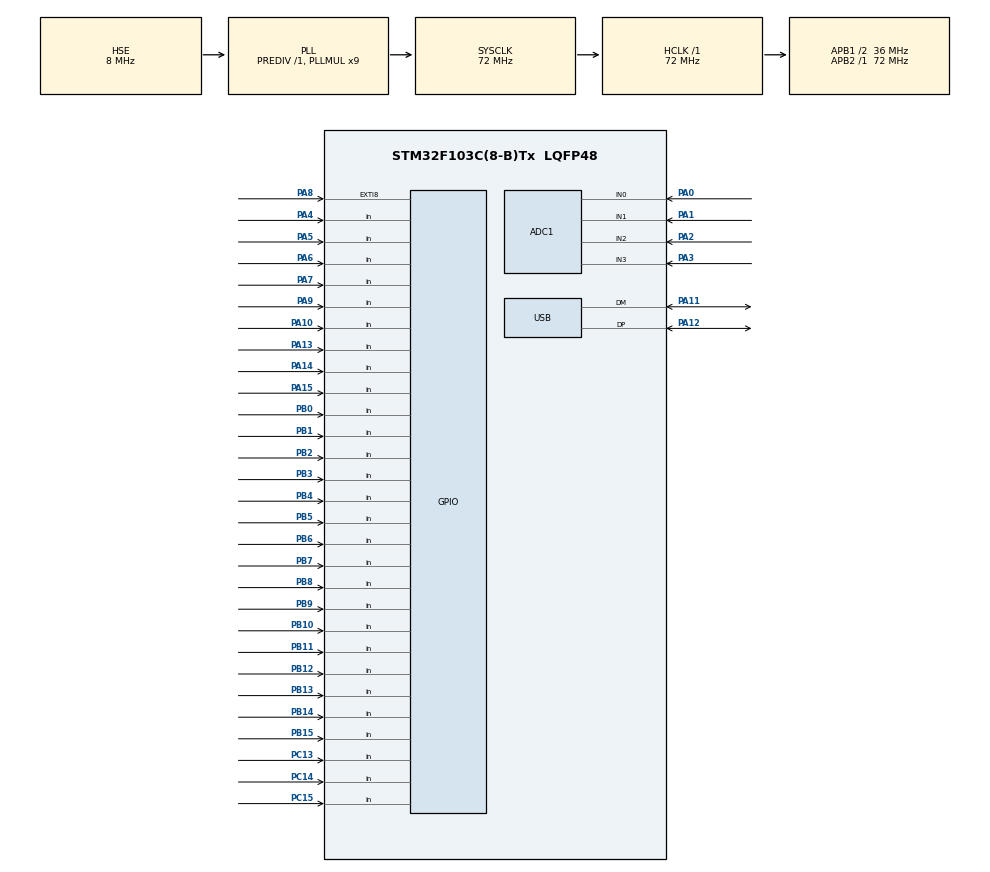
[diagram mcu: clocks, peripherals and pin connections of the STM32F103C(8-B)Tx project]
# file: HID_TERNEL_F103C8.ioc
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ADC1.Channel-0\#ChannelRegularConversion=ADC_CHANNEL_0
ADC1.Channel-1\#ChannelRegularConversion=ADC_CHANNEL_1
ADC1.Channel-2\#ChannelRegularConversion=ADC_CHANNEL_2
ADC1.Channel-3\#ChannelRegularConversion=ADC_CHANNEL_3
ADC1.ContinuousConvMode=ENABLE
ADC1.NbrOfConversion=4
ADC1.NbrOfConversionFlag=1
ADC1.Rank-0\#ChannelRegularConversion=1
ADC1.Rank-1\#ChannelRegularConversion=2
ADC1.Rank-2\#ChannelRegularConversion=3
ADC1.Rank-3\#ChannelRegularConversion=4
ADC1.SamplingTime-0\#ChannelRegularConversion=ADC_SAMPLETIME_71CYCLES_5
ADC1.SamplingTime-1\#ChannelRegularConversion=ADC_SAMPLETIME_71CYCLES_5
ADC1.SamplingTime-2\#ChannelRegularConversion=ADC_SAMPLETIME_71CYCLES_5
ADC1.SamplingTime-3\#ChannelRegularConversion=ADC_SAMPLETIME_71CYCLES_5
ADC1.master=1
Dma.ADC1.0.Direction=DMA_PERIPH_TO_MEMORY
Dma.ADC1.0.Instance=DMA1_Channel1
Dma.ADC1.0.MemDataAlignment=DMA_MDATAALIGN_HALFWORD
Dma.ADC1.0.MemInc=DMA_MINC_ENABLE
Dma.ADC1.0.Mode=DMA_CIRCULAR
Dma.ADC1.0.PeriphDataAlignment=DMA_PDATAALIGN_HALFWORD
Dma.ADC1.0.PeriphInc=DMA_PINC_DISABLE
Dma.ADC1.0.Priority=DMA_PRIORITY_MEDIUM
Dma.Request0=ADC1
Mcu.Family=STM32F1
Mcu.Name=STM32F103C(8-B)Tx
Mcu.Package=LQFP48
NVIC.ADC1_2_IRQn=true\:0\:0\:false\:false\:true\:true\:true\:true
NVIC.DMA1_Channel1_IRQn=true\:0\:0\:false\:false\:true\:false\:true\:true
NVIC.PriorityGroup=NVIC_PRIORITYGROUP_4
NVIC.TIM2_IRQn=true\:0\:0\:false\:false\:true\:true\:true\:true
NVIC.USB_LP_CAN1_RX0_IRQn=true\:0\:0\:false\:false\:true\:false\:true\:true
PA0-WKUP.Signal=ADCx_IN0
PA1.Signal=ADCx_IN1
PA10.Signal=GPIO_Input
PA11.Mode=Device
PA11.Signal=USB_DM
PA12.Mode=Device
PA12.Signal=USB_DP
PA13.Signal=GPIO_Input
PA14.Signal=GPIO_Input
PA15.Signal=GPIO_Input
PA2.Signal=ADCx_IN2
PA3.Signal=ADCx_IN3
PA4.Signal=GPIO_Input
PA5.Signal=GPIO_Input
PA6.Signal=GPIO_Input
PA7.Signal=GPIO_Input
PA8.Signal=GPXTI8
PA9.Signal=GPIO_Input
PB0.Signal=GPIO_Input
PB1.Signal=GPIO_Input
PB10.Signal=GPIO_Input
PB11.Signal=GPIO_Input
PB12.Signal=GPIO_Input
PB13.Signal=GPIO_Input
PB14.Signal=GPIO_Input
PB15.Signal=GPIO_Input
PB2.Signal=GPIO_Input
PB3.Signal=GPIO_Input
PB4.Signal=GPIO_Input
PB5.Signal=GPIO_Input
PB6.Signal=GPIO_Input
PB7.Signal=GPIO_Input
PB8.Signal=GPIO_Input
PB9.Signal=GPIO_Input
PC13-TAMPER-RTC.Signal=GPIO_Input
PC14-OSC32_IN.Signal=GPIO_Input
PC15-OSC32_OUT.Signal=GPIO_Input
PD0-OSC_IN.Mode=HSE-External-Oscillator
PD0-OSC_IN.Signal=RCC_OSC_IN
PD1-OSC_OUT.Mode=HSE-External-Oscillator
PD1-OSC_OUT.Signal=RCC_OSC_OUT
ProjectManager.HeapSize=0x200
ProjectManager.StackSize=0x400
ProjectManager.TargetToolchain=Makefile
RCC.ADCPresc=RCC_ADCPCLK2_DIV6
RCC.AHBFreq_Value=72000000
RCC.APB1CLKDivider=RCC_HCLK_DIV2
RCC.APB1Freq_Value=36000000
RCC.APB1TimFreq_Value=72000000
RCC.APB2Freq_Value=72000000
RCC.APB2TimFreq_Value=72000000
RCC.HCLKFreq_Value=72000000
RCC.PLLMUL=RCC_PLL_MUL9
RCC.SYSCLKFreq_VALUE=72000000
RCC.SYSCLKSource=RCC_SYSCLKSOURCE_PLLCLK
RCC.USBFreq_Value=48000000
RCC.USBPrescaler=RCC_USBCLKSOURCE_PLL_DIV1_5
SH.ADCx_IN0.0=ADC1_IN0,IN0
SH.ADCx_IN1.0=ADC1_IN1,IN1
SH.ADCx_IN2.0=ADC1_IN2,IN2
SH.ADCx_IN3.0=ADC1_IN3,IN3
TIM2.AutoReloadPreload=TIM_AUTORELOAD_PRELOAD_ENABLE
TIM2.Period=99
TIM2.Prescaler=71
USB_DEVICE.CLASS_NAME_FS=CUSTOM_HID
USB_DEVICE.CUSTOM_HID_FS_BINTERVAL=0x1
USB_DEVICE.MANUFACTURER_STRING=STMicroelectronics
USB_DEVICE.PID_CUSTOMHID_FS=22353
USB_DEVICE.PRODUCT_STRING_CUSTOMHID_FS=HID_throttle
USB_DEVICE.USBD_CUSTOMHID_OUTREPORT_BUF_SIZE=64
USB_DEVICE.USBD_CUSTOM_HID_REPORT_DESC_SIZE=50
USB_DEVICE.VID=1154
USB_DEVICE.VirtualMode=CustomHid
USB_DEVICE.VirtualModeFS=Custom_Hid_FS
VP_SYS_VS_ND.Mode=No_Debug
VP_TIM2_VS_ClockSourceINT.Mode=Internal
VP_USB_DEVICE_VS_USB_DEVICE_CUSTOM_HID_FS.Mode=CUSTOM_HID_FS
board=custom

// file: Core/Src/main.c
/* USER CODE BEGIN Header */
/**
  ******************************************************************************
  * @file           : main.c
  * @brief          : Main program body
  ******************************************************************************
  * @attention
  *
  * Copyright (c) 2025 STMicroelectronics.
  * All rights reserved.
  *
  * This software is licensed under terms that can be found in the LICENSE file
  * in the root directory of this software component.
  * If no LICENSE file comes with this software, it is provided AS-IS.
  *
  ******************************************************************************
  */
/* USER CODE END Header */
#include "main.h"
#include "adc.h"
#include "dma.h"
#include "tim.h"
#include "usb_device.h"
#include "gpio.h"

/* USER CODE BEGIN Includes */
#include "hid_device_for_handel.h"
/* USER CODE END Includes */

void SystemClock_Config(void);

int main(void)
{

  /* MCU Configuration--------------------------------------------------------*/

  /* Reset of all peripherals, Initializes the Flash interface and the Systick. */
  HAL_Init();

  /* Configure the system clock */
  SystemClock_Config();

  /* Initialize all configured peripherals */
  MX_GPIO_Init();
  MX_DMA_Init();
  MX_ADC1_Init();
  MX_TIM2_Init();
  MX_USB_DEVICE_Init();
  /* USER CODE BEGIN 2 */
  HID_FLIGHT_SIMULATOR_SYS_START();

  /* USER CODE END 2 */

  /* Infinite loop */
  /* USER CODE BEGIN WHILE */
  while (1)
  {
    HID_FLIGHT_SIMULATOR_SYS_LOOP();
    /* USER CODE END WHILE */

  }
}

void SystemClock_Config(void)
{
  RCC_OscInitTypeDef RCC_OscInitStruct = {0};
  RCC_ClkInitTypeDef RCC_ClkInitStruct = {0};
  RCC_PeriphCLKInitTypeDef PeriphClkInit = {0};

  /** Initializes the RCC Oscillators according to the specified parameters
  * in the RCC_OscInitTypeDef structure.
  */
  RCC_OscInitStruct.OscillatorType = RCC_OSCILLATORTYPE_HSE;
  RCC_OscInitStruct.HSEState = RCC_HSE_ON;
  RCC_OscInitStruct.HSEPredivValue = RCC_HSE_PREDIV_DIV1;
  RCC_OscInitStruct.HSIState = RCC_HSI_ON;
  RCC_OscInitStruct.PLL.PLLState = RCC_PLL_ON;
  RCC_OscInitStruct.PLL.PLLSource = RCC_PLLSOURCE_HSE;
  RCC_OscInitStruct.PLL.PLLMUL = RCC_PLL_MUL9;
  if (HAL_RCC_OscConfig(&RCC_OscInitStruct) != HAL_OK)
  {
    Error_Handler();
  }

  /** Initializes the CPU, AHB and APB buses clocks
  */
  RCC_ClkInitStruct.ClockType = RCC_CLOCKTYPE_HCLK|RCC_CLOCKTYPE_SYSCLK
                              |RCC_CLOCKTYPE_PCLK1|RCC_CLOCKTYPE_PCLK2;
  RCC_ClkInitStruct.SYSCLKSource = RCC_SYSCLKSOURCE_PLLCLK;
  RCC_ClkInitStruct.AHBCLKDivider = RCC_SYSCLK_DIV1;
  RCC_ClkInitStruct.APB1CLKDivider = RCC_HCLK_DIV2;
  RCC_ClkInitStruct.APB2CLKDivider = RCC_HCLK_DIV1;

  if (HAL_RCC_ClockConfig(&RCC_ClkInitStruct, FLASH_LATENCY_2) != HAL_OK)
  {
    Error_Handler();
  }
  PeriphClkInit.PeriphClockSelection = RCC_PERIPHCLK_ADC|RCC_PERIPHCLK_USB;
  PeriphClkInit.AdcClockSelection = RCC_ADCPCLK2_DIV6;
  PeriphClkInit.UsbClockSelection = RCC_USBCLKSOURCE_PLL_DIV1_5;
  if (HAL_RCCEx_PeriphCLKConfig(&PeriphClkInit) != HAL_OK)
  {
    Error_Handler();
  }
}

void Error_Handler(void)
{
  __disable_irq();
  while (1)
  {
  }
}
